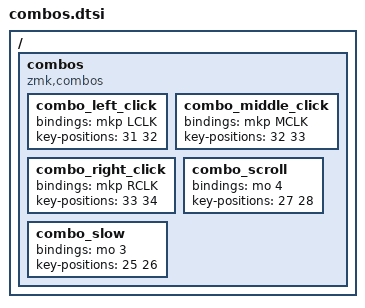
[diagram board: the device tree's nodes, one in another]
/ {
    combos {
        compatible = "zmk,combos";


        combo_left_click {
            bindings = <&mkp LCLK>;
            key-positions = <31 32>;
        };
        
        combo_middle_click {
            bindings = <&mkp MCLK>;
            key-positions = <32 33>;
        };

        combo_right_click {
            bindings = <&mkp RCLK>;
            key-positions = <33 34>;
        };

        combo_scroll {
            bindings = <&mo 4>;
            key-positions = <27 28>;
        };

        combo_slow {
            bindings = <&mo 3>;
            key-positions = <25 26>;
        };
    };
};
